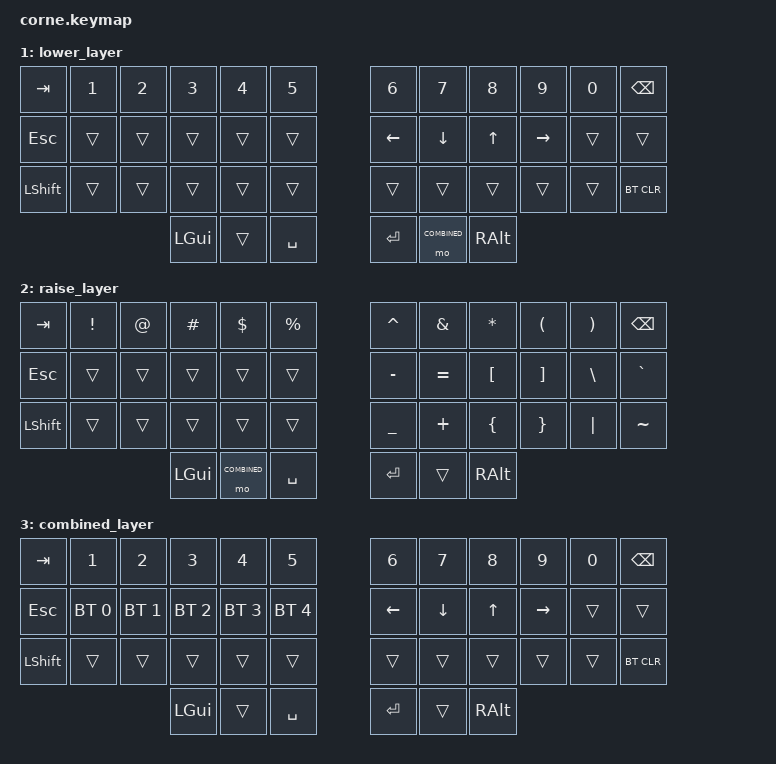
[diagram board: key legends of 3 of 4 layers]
/*
 * Copyright (c) 2020 The ZMK Contributors
 *
 * SPDX-License-Identifier: MIT
 */

#include <behaviors.dtsi>
#include <dt-bindings/zmk/keys.h>
#include <dt-bindings/zmk/bt.h>

#define HRML(k1,k2,k3,k4) &mt LSHFT k1 &mt LALT k2 &mt LCTRL k3 &mt LGUI k4
#define HRMR(k1,k2,k3,k4) &mt RGUI k1 &mt RCTRL k2 &mt RALT  k3 &mt RSHFT k4
#define COMBINED 3

// &nice_view_spi {
    // cs-gpios = <&pro_micro 0 GPIO_ACTIVE_HIGH>;
// };

&mt {
  tapping-term-ms = <200>;
  quick_tap_ms = <0>;
  flavor = "tap-preferred";
};

/ {
        keymap {

                compatible = "zmk,keymap";

                default_layer {
// -----------------------------------------------------------------------------------------
// | TAB  |  Q  |  W  |  E  |  R  |  T  |   |  Y  |  U   |  I  |  O  |  P  | BKSP |
// | ESC  |  A  |  S  |  D  |  F  |  G  |   |  H  |  J   |  K  |  L  |  ;  |  '   |
// | SHFT |  Z  |  X  |  C  |  V  |  B  |   |  N  |  M   |  ,  |  .  |  /  | DEL  |
//                    | GUI | LWR | SPC |   | ENT | RSE  | ALT |
                        bindings = <
   &kp TAB   &kp Q &kp W &kp E &kp R &kp T   &kp Y &kp U  &kp I     &kp O   &kp P    &kp BSPC
   &kp ESC   HRML(A,   S,    D,   F) &kp G   &kp H HRMR(J,    K,        L,   SEMI)   &kp SQT
   &kp LSHFT &kp Z &kp X &kp C &kp V &kp B   &kp N &kp M  &kp COMMA &kp DOT &kp FSLH &kp DEL
                  &kp LGUI &mo 1 &kp SPACE   &kp RET &mo 2 &kp RALT
                        >;
                };
                lower_layer {
// -----------------------------------------------------------------------------------------
// |  TAB |  1   |  2  |  3  |  4  |  5  |   |  6  |  7  |  8  |  9  |  0  | BKSP    |
// | ESC  | BT1  | BT2 | BT3 | BT4 | BT5 |   | LFT | DWN |  UP | RGT |     | RGB_TOG |
// | SHFT |      |     |     |     |     |   |     |     |     |     |     | BT_CLR  |
//                     | GUI |     | SPC |   | ENT | RSE | ALT |
                        bindings = <
   &kp TAB    &kp N1  &kp N2  &kp N3  &kp N4    &kp N5  &kp N6     &kp N7       &kp N8 &kp N9    &kp N0 &kp BSPC
   &kp ESC    &trans  &trans  &trans  &trans    &trans  &kp LEFT   &kp DOWN     &kp UP &kp RIGHT &trans &trans
   &kp LSHFT  &trans  &trans  &trans  &trans    &trans  &trans     &trans       &trans &trans    &trans &bt BT_CLR
                                    &kp LGUI    &trans  &kp SPACE  &kp RET  &mo COMBINED  &kp RALT
                        >;
                };

                raise_layer {
// -----------------------------------------------------------------------------------------
// | TAB  |  !  |  @  |  #  |  $  |  %  |   |  ^  |  &  |  *  |  (  |  )  | BKSP |
// | ESC  |     |     |     |     |     |   |  -  |  =  |  [  |  ]  |  \  |  `   |
// | SHFT |     |     |     |     |     |   |  _  |  +  |  {  |  }  | "|" |  ~   |
//                    | GUI |     | SPC |   | ENT |     | ALT |
                        bindings = <
   &kp TAB   &kp EXCL &kp AT &kp HASH &kp DLLR       &kp PRCNT   &kp CARET &kp AMPS  &kp ASTRK &kp LPAR &kp RPAR &kp BSPC
   &kp ESC   &trans   &trans &trans   &trans         &trans      &kp MINUS &kp EQUAL &kp LBKT  &kp RBKT &kp BSLH &kp GRAVE
   &kp LSHFT &trans   &trans &trans   &trans         &trans      &kp UNDER &kp PLUS  &kp LBRC  &kp RBRC &kp PIPE &kp TILDE
                             &kp LGUI &mo COMBINED   &kp SPACE   &kp RET   &trans    &kp RALT
                        >;
                };


                combined_layer {
// -----------------------------------------------------------------------------------------
// |  TAB |  1   |  2  |  3  |  4  |  5  |   |  6  |  7  |  8  |  9  |  0  | BKSP    |
// | ESC  | BT1  | BT2 | BT3 | BT4 | BT5 |   | LFT | DWN |  UP | RGT |     | RGB_TOG |
// | SHFT |      |     |     |     |     |   |     |     |     |     |     | BT_CLR  |
//                     | GUI |     | SPC |   | ENT | RSE | ALT |
                        bindings = <
   &kp TAB    &kp N1     &kp N2       &kp N3       &kp N4       &kp N5      &kp N6   &kp N7        &kp N8 &kp N9    &kp N0 &kp BSPC
   &kp ESC  &bt BT_SEL 0 &bt BT_SEL 1 &bt BT_SEL 2 &bt BT_SEL 3 &bt BT_SEL 4  &kp LEFT &kp DOWN      &kp UP &kp RIGHT &trans &trans
   &kp LSHFT  &trans   &trans       &trans       &trans       &trans          &trans   &trans        &trans &trans    &trans &bt BT_CLR
                                    &kp LGUI     &trans       &kp SPACE       &kp RET  &trans  &kp RALT
                        >;
                };
        };
};
